VERSION ""

NS_ :

BS_:

BU_: VT TC Sprayer TECU

BO_ 2566835198 DM2: 22 Vector__XXX
 SG_ DTC5 : 144|32@1+ (1,0) [0|4294967295] "" Vector__XXX
 SG_ DTC4 : 112|32@1+ (1,0) [0|4294967295] "" Vector__XXX
 SG_ DTC3 : 80|32@1+ (1,0) [0|4294967295] "" Vector__XXX
 SG_ DTC2 : 48|32@1+ (1,0) [0|4294967295] "" Vector__XXX
 SG_ DTC1 : 16|32@1+ (1,0) [0|4294967295] "" Vector__XXX

BO_ 2566734590 ICC: 8 Vector__XXX
 SG_ CertLaboratoryType_FirstDef m0 : 9|3@1+ (1,0) [0|7] "" Vector__XXX
 SG_ TestProtocolRevision_MSBits m1 : 11|2@1+ (1,0) [0|0] "" Vector__XXX
 SG_ MessageRevision M : 47|1@1+ (1,0) [0|0] "" Vector__XXX
 SG_ CertificationReferenceNumber : 48|16@1+ (1,0) [0|65535] "" Vector__XXX
 SG_ CertTypeTaskController m0 : 39|1@1+ (1,0) [0|1] "" Vector__XXX
 SG_ CertTypeTCWorkingSetMaster m0 : 38|1@1+ (1,0) [0|1] "" Vector__XXX
 SG_ CertTypeTCWorkingSetMember m0 : 37|1@1+ (1,0) [0|1] "" Vector__XXX
 SG_ CertTypeFileServer m0 : 36|1@1+ (1,0) [0|1] "" Vector__XXX
 SG_ CertTypeGPSReceiver m0 : 35|1@1+ (1,0) [0|1] "" Vector__XXX
 SG_ CertTypeMinimumECU m0 : 31|1@1+ (1,0) [0|1] "" Vector__XXX
 SG_ CertTypeTECUClass1 m0 : 30|1@1+ (1,0) [0|1] "" Vector__XXX
 SG_ CertTypeTECUClass2 m0 : 29|1@1+ (1,0) [0|1] "" Vector__XXX
 SG_ CertTypeTECUClass3 m0 : 28|1@1+ (1,0) [0|1] "" Vector__XXX
 SG_ CertTypeClass3ECU m0 : 27|1@1+ (1,0) [0|1] "" Vector__XXX
 SG_ CertTypeVirtualTerminal m0 : 26|1@1+ (1,0) [0|1] "" Vector__XXX
 SG_ CertTypeVTWorkingSetMaster m0 : 25|1@1+ (1,0) [0|1] "" Vector__XXX
 SG_ CertTypeVTWorkingSetMember m0 : 24|1@1+ (1,0) [0|1] "" Vector__XXX
 SG_ CertificationLaboratoryID : 13|11@1+ (1,0) [0|2047] "" Vector__XXX
 SG_ CertLaboratoryType_SecondDef m1 : 9|2@1+ (1,0) [0|3] "" Vector__XXX
 SG_ TestProtocolRevision : 6|3@1+ (1,0) [0|7] "" Vector__XXX
 SG_ TestProtocolPublicationYear : 0|6@1+ (1,2000) [2000|2061] "year" Vector__XXX

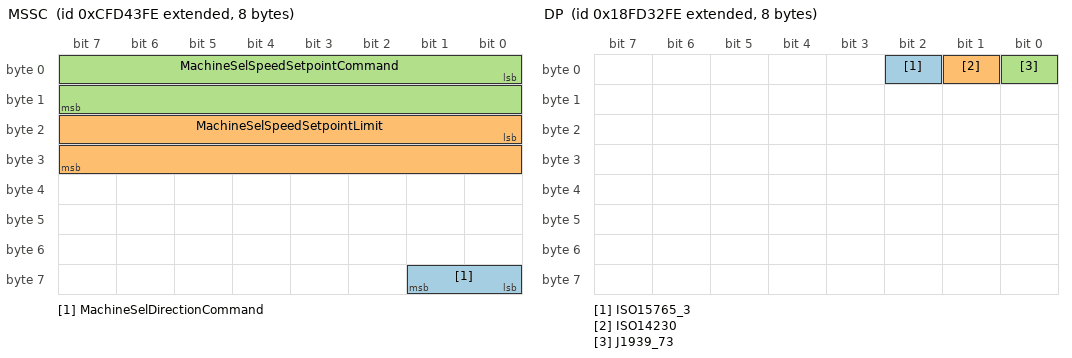
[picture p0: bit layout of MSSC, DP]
BO_ 2365408254 MSSC: 8 Vector__XXX
 SG_ MachineSelDirectionCommand : 56|2@1+ (1,0) [0|3] "" Vector__XXX
 SG_ MachineSelSpeedSetpointLimit : 16|16@1+ (0.001,0) [0|64255] "m/s" Vector__XXX
 SG_ MachineSelSpeedSetpointCommand : 0|16@1+ (0.001,0) [0|64255] "m/s" Vector__XXX

BO_ 2566730494 DP: 8 Vector__XXX
 SG_ ISO15765_3 : 2|1@1+ (1,0) [0|1] "" Vector__XXX
 SG_ ISO14230 : 1|1@1+ (1,0) [0|1] "" Vector__XXX
 SG_ J1939_73 : 0|1@1+ (1,0) [0|1] "" Vector__XXX

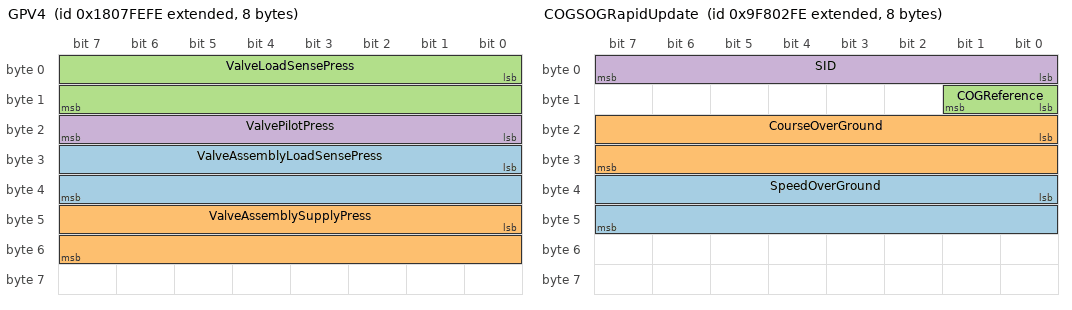
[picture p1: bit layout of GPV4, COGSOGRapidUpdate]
BO_ 2550660862 GPV4: 8 Vector__XXX
 SG_ ValveAssemblyLoadSensePress : 24|16@1+ (5,0) [0|321275] "kPa" Vector__XXX
 SG_ ValveAssemblySupplyPress : 40|16@1+ (5,0) [0|321275] "kPa" Vector__XXX
 SG_ ValveLoadSensePress : 0|16@1+ (5,0) [0|321275] "kPa" Vector__XXX
 SG_ ValvePilotPress : 16|8@1+ (16,0) [0|4000] "kPa" Vector__XXX

BO_ 2364547838 MSS: 9 Vector__XXX
 SG_ MachineSelectedSpeedLimitStatus : 61|3@1+ (1,0) [0|7] "" Vector__XXX
 SG_ MachineSelectedSpeedSource : 58|3@1+ (1,0) [0|7] "" Vector__XXX
 SG_ MachineSelectedDirection : 56|2@1+ (1,0) [0|3] "" Vector__XXX
 SG_ MachineSelectedDistance : 16|32@1+ (0.001,0) [0|4211081.215] "m" Vector__XXX
 SG_ MachineSelectedSpeed : 0|16@1+ (0.001,0) [0|65.535] "m/s" Vector__XXX

BO_ 2566835454 DM3: 0 Vector__XXX

BO_ 2365391616 IOS: 8 Vector__XXX
 SG_ ImplementOperatingStateCmd : 56|2@1+ (1,0) [0|3] "" Vector__XXX

BO_ 2365391360 AISO: 8 Vector__XXX
 SG_ StopAllImplOpTransitionNum : 48|8@1+ (1,0) [0|0] "" Vector__XXX
 SG_ StopAllImplementOperations : 56|2@1- (1,0) [0|3] "" Vector__XXX

BO_ 2314732286 COGSOGRapidUpdate: 8 Vector__XXX
 SG_ SpeedOverGround : 32|16@1+ (0.01,0) [0|655.32] "m/s" Vector__XXX
 SG_ CourseOverGround : 16|16@1+ (0.0001,0) [0|6.28318] "rad" Vector__XXX
 SG_ COGReference : 8|2@1+ (1,0) [0|3] "" Vector__XXX
 SG_ SID : 0|8@1+ (1,0) [0|252] "" Vector__XXX

BO_ 2358181630 SCMCC: 8 Vector__XXX
 SG_ MaxDesignatorStringLength m144 : 32|16@1+ (1,0) [0|65535] "" Vector__XXX
 SG_ BusyFlagParsing m149 : 33|1@1+ (1,0) [0|1] "" Vector__XXX
 SG_ ReceivedTAN m50 : 32|8@1+ (1,0) [0|255] "" Vector__XXX
 SG_ RecordedFunctionValue m51 : 32|32@1+ (1,0) [0|4294967295] "" Vector__XXX
 SG_ BusyFlagMemoryAccess m149 : 32|1@1+ (1,0) [0|1] "" Vector__XXX
 SG_ ExecutionIndicationResponseError m50 : 24|8@1+ (1,0) [0|255] "" Vector__XXX
 SG_ TAN m51 : 24|8@1+ (1,0) [0|255] "" Vector__XXX
 SG_ SequenceState m149 : 24|8@1+ (1,0) [0|255] "" Vector__XXX
 SG_ ReasonIndicator m48 : 24|8@1+ (1,0) [0|255] "" Vector__XXX
 SG_ GraphicsHeight m144 : 24|8@1+ (1,0) [32|255] "" Vector__XXX
 SG_ FunctionExecutionState m50 : 22|2@1+ (1,0) [0|3] "" Vector__XXX
 SG_ FunctionExecutionStateAck m52 : 22|2@1+ (1,0) [0|3] "" Vector__XXX
 SG_ StateID m50 : 16|6@1+ (1,0) [0|63] "" Vector__XXX
 SG_ ActualConfigurationLabel m0 : 16|8@1+ (1,0) [0|255] "" Vector__XXX
 SG_ ActualVersionLabel m0 : 16|8@1+ (1,0) [0|255] "" Vector__XXX
 SG_ GraphicsWidth m144 : 16|8@1+ (1,0) [32|255] "" Vector__XXX
 SG_ RecordedStateID m51 : 16|6@1+ (1,0) [0|63] "" Vector__XXX
 SG_ SequenceNumber m149 : 16|8@1+ (1,0) [0|255] "" Vector__XXX
 SG_ ObjectIdOfFirstFaultyObject m4 : 16|16@1+ (1,0) [0|65535] "" Vector__XXX
 SG_ RecordedFunctionID m51 : 8|8@1+ (1,0) [0|255] "" Vector__XXX
 SG_ MemoryStatus m145 : 8|8@1+ (1,0) [0|1] "" Vector__XXX
 SG_ VersionResponseError m1M : 8|8@1+ (1,0) [0|255] "" Vector__XXX
 SG_ ConfigLabelResponseError m2M : 8|8@1+ (1,0) [0|255] "" Vector__XXX
 SG_ TransferResponseError m3 : 8|8@1+ (1,0) [0|255] "" Vector__XXX
 SG_ ActivationResponseError m4 : 8|8@1+ (1,0) [0|255] "" Vector__XXX
 SG_ SCMState m149 : 8|8@1+ (1,0) [0|2] "" Vector__XXX
 SG_ FunctionID m50 : 8|8@1+ (1,0) [0|255] "" Vector__XXX
 SG_ SCVersion m144 : 8|8@1+ (1,0) [0|255] "" Vector__XXX
 SG_ CommandedSCCState m48 : 8|8@1+ (1,0) [0|1] "" Vector__XXX
 SG_ DeleteCommandResponseError m5 : 8|8@1+ (1,0) [0|255] "" Vector__XXX
 SG_ StoreCommandError m6 : 8|8@1+ (1,0) [0|255] "" Vector__XXX
 SG_ LoadResponseError m7 : 8|8@1+ (1,0) [0|255] "" Vector__XXX
 SG_ MessageCode M : 0|8@1+ (1,0) [0|255] "" Vector__XXX

BO_ 2358116094 SCCCM: 8 Vector__XXX
 SG_ OperatorConfirmationRequired3 m3 : 63|1@1+ (1,0) [0|1] "" Vector__XXX
 SG_ ClientFunctionErrorStatuts3 m3 : 56|4@1+ (1,0) [0|15] "" Vector__XXX
 SG_ IDOfFaultyClientFunction3 m3 : 48|8@1+ (1,0) [0|255] "" Vector__XXX
 SG_ OperatorConfirmationRequired2 m2 : 47|1@1+ (1,0) [0|1] "" Vector__XXX
 SG_ ClientFunctionErrorStatuts2 m2 : 40|4@1+ (1,0) [0|15] "" Vector__XXX
 SG_ ReceivedTAN m52 : 32|8@1+ (1,0) [0|255] "" Vector__XXX
 SG_ FunctionValue m0 : 32|32@1+ (1,0) [0|4294967295] "" Vector__XXX
 SG_ IDOfFaultyClientFunction2 m2 : 32|8@1+ (1,0) [0|255] "" Vector__XXX
 SG_ ClientFunctonErrorState m150 : 32|8@1+ (1,0) [0|255] "" Vector__XXX
 SG_ OperatorConfirmationRequired1 m1 : 31|1@1+ (1,0) [0|1] "" Vector__XXX
 SG_ TAN m50 : 24|8@1+ (1,0) [0|255] "" Vector__XXX
 SG_ ClientExecutionError m52 : 24|8@1+ (1,0) [0|255] "" Vector__XXX
 SG_ ClientFunctionErrorStatuts1 m1 : 24|4@1+ (1,0) [0|15] "" Vector__XXX
 SG_ ClientAbortError m49 : 24|8@1+ (1,0) [0|255] "" Vector__XXX
 SG_ SequenceState m150 : 24|8@1+ (1,0) [0|255] "" Vector__XXX
 SG_ FunctionExecutionState m50M : 22|2@1+ (1,0) [0|3] "" Vector__XXX
 SG_ NewFunctionExecutionState m52 : 22|2@1+ (1,0) [0|3] "" Vector__XXX
 SG_ NewStateID m52 : 16|6@1+ (1,0) [0|63] "" Vector__XXX
 SG_ IDOfFaultyClientFunction1 m1 : 16|8@1+ (1,0) [0|255] "" Vector__XXX
 SG_ StateID m50 : 16|6@1+ (1,0) [0|63] "" Vector__XXX
 SG_ SequenceNumber m150 : 16|8@1+ (1,0) [0|255] "" Vector__XXX
 SG_ NumberOfFaultyFunctions m53M : 8|8@1+ (1,0) [0|255] "" Vector__XXX
 SG_ RecordedFunctionID m52 : 8|8@1+ (1,0) [0|255] "" Vector__XXX
 SG_ SCCState m150 : 8|8@1+ (1,0) [0|2] "" Vector__XXX
 SG_ FunctionID m50 : 8|8@1+ (1,0) [0|255] "" Vector__XXX
 SG_ MemoryRequired m145 : 8|32@1+ (1,0) [0|4294967295] "bytes" Vector__XXX
 SG_ AddressSCCWSM m4 : 8|8@1+ (1,0) [0|253] "" Vector__XXX
 SG_ DeleteCommandType m5 : 8|8@1+ (1,0) [0|1] "" Vector__XXX
 SG_ MessageCode M : 0|8@1+ (1,0) [0|255] "" Vector__XXX

BO_ 2559835902 NM: 8 Vector__XXX
 SG_ ManufacturerCodeQualifierFlag m0 : 8|1@1+ (1,0) [0|1] "" Vector__XXX
 SG_ ECUInstanceQualifierFlag m0 : 9|1@1+ (1,0) [0|1] "" Vector__XXX
 SG_ FunctionInstanceQualifierFlag m0 : 10|1@1+ (1,0) [0|1] "" Vector__XXX
 SG_ FunctionQualifierFlag m0 : 11|1@1+ (1,0) [0|1] "" Vector__XXX
 SG_ VehicleSystemQualifierFlag m0 : 12|1@1+ (1,0) [0|1] "" Vector__XXX
 SG_ VehicleSystemInstanceQualifierFl m0 : 13|1@1+ (1,0) [0|1] "" Vector__XXX
 SG_ IndustryGroupQualifierFlag m0 : 14|1@1+ (1,0) [0|1] "" Vector__XXX
 SG_ ArbitraryAddressCapableQualifier m0 : 15|1@1+ (1,0) [0|1] "" Vector__XXX
 SG_ NMControlModeIndicator M : 16|4@1+ (1,0) [0|15] "" Vector__XXX
 SG_ CommandManufacturerCode m0 : 21|11@1+ (1,0) [0|2047] "" Vector__XXX
 SG_ CommandECUInstance m0 : 32|3@1+ (1,0) [0|7] "" Vector__XXX
 SG_ CommandFunctionInstance m0 : 35|5@1+ (1,0) [0|31] "" Vector__XXX
 SG_ CommandFunction m0 : 40|8@1+ (1,0) [0|255] "" Vector__XXX
 SG_ CommandVehicleSystem m0 : 49|7@1+ (1,0) [0|127] "" Vector__XXX
 SG_ CommandIndustryGroup m0 : 60|3@1+ (1,0) [0|7] "" Vector__XXX
 SG_ CommandVehicleSystemInstance m0 : 56|4@1+ (1,0) [0|15] "" Vector__XXX
 SG_ CommandArbitraryAddressCapable m0 : 63|1@1+ (1,0) [0|1] "" Vector__XXX
 SG_ ErrorCode m4 : 0|8@1+ (1,0) [0|0] "" Vector__XXX
 SG_ NameChecksum m0 : 0|8@1+ (1,0) [0|0] "" Vector__XXX

BO_ 2566843646 VI: 8 Vector__XXX
 SG_ VehicleIdentificationNumber : 0|8@1+ (1,0) [0|255] "per byte" Vector__XXX

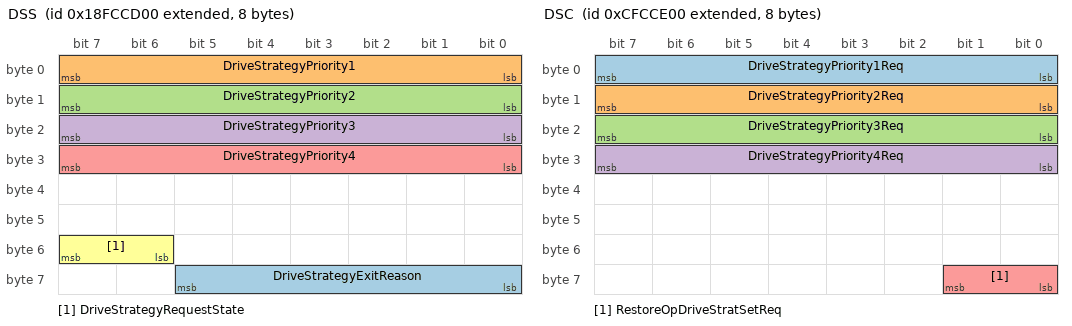
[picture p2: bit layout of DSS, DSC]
BO_ 2566704384 DSS: 8 Vector__XXX
 SG_ DriveStrategyExitReason : 56|6@1+ (1,0) [0|63] "" Vector__XXX
 SG_ DriveStrategyPriority1 : 0|8@1+ (1,0) [0|255] "" Vector__XXX
 SG_ DriveStrategyPriority2 : 8|8@1+ (1,0) [0|255] "" Vector__XXX
 SG_ DriveStrategyPriority3 : 16|8@1+ (1,0) [0|255] "" Vector__XXX
 SG_ DriveStrategyPriority4 : 24|8@1+ (1,0) [0|255] "" Vector__XXX
 SG_ DriveStrategyRequestState : 54|2@1+ (1,0) [0|3] "" Vector__XXX

BO_ 2365378048 DSC: 8 Vector__XXX
 SG_ DriveStrategyPriority1Req : 0|8@1+ (1,0) [0|255] "" Vector__XXX
 SG_ DriveStrategyPriority2Req : 8|8@1+ (1,0) [0|255] "" Vector__XXX
 SG_ DriveStrategyPriority3Req : 16|8@1+ (1,0) [0|255] "" Vector__XXX
 SG_ DriveStrategyPriority4Req : 24|8@1+ (1,0) [0|255] "" Vector__XXX
 SG_ RestoreOpDriveStratSetReq : 56|2@1+ (1,0) [0|3] "" Vector__XXX

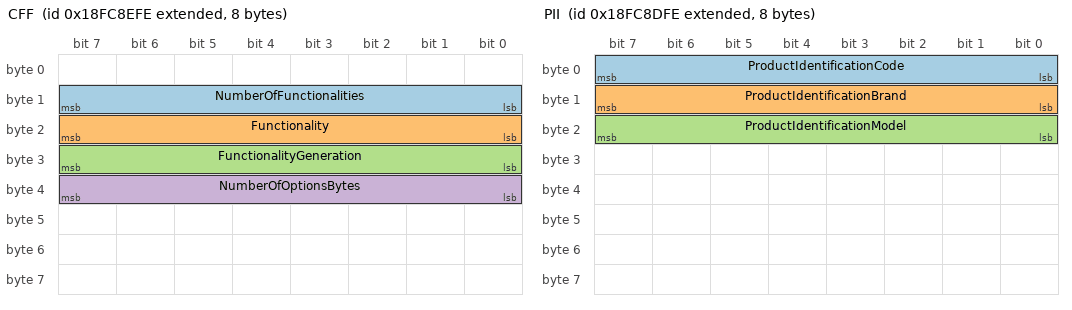
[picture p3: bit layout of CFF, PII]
BO_ 2566688510 CFF: 8 Vector__XXX
 SG_ NumberOfFunctionalities : 8|8@1- (1,0) [1|255] "" Vector__XXX
 SG_ Functionality : 16|8@1- (1,0) [0|255] "" Vector__XXX
 SG_ FunctionalityGeneration : 24|8@1- (1,0) [1|255] "" Vector__XXX
 SG_ NumberOfOptionsBytes : 32|8@1- (1,0) [0|255] "" Vector__XXX

BO_ 2566688254 PII: 8 Vector__XXX
 SG_ ProductIdentificationCode : 0|8@1- (1,0) [0|0] "" Vector__XXX
 SG_ ProductIdentificationBrand : 8|8@1- (1,0) [0|0] "" Vector__XXX
 SG_ ProductIdentificationModel : 16|8@1- (1,0) [0|0] "" Vector__XXX

CM_ BO_ 2566835198 "Previously active diagnostic trouble codes";
CM_ SG_ 2566835198 DTC5 "Diagnostic Trouble Code";
CM_ SG_ 2566835198 DTC4 "Diagnostic Trouble Code";
CM_ SG_ 2566835198 DTC3 "Diagnostic Trouble Code";
CM_ SG_ 2566835198 DTC2 "Diagnostic Trouble Code";
CM_ SG_ 2566835198 DTC1 "Diagnostic Trouble Code";
CM_ BO_ 2566734590 "ISOBUS compliance certification";
CM_ SG_ 2566734590 CertLaboratoryType_FirstDef "Approving body for the certification laboratory.";
CM_ SG_ 2566734590 MessageRevision "This parameter distinguishes the format of the ISOBUS Compliance Certification message in the second 
edition from the format in the third and later editions.";
CM_ SG_ 2566734590 CertificationReferenceNumber "ISOBUS Compliance certification reference number";
CM_ SG_ 2566734590 CertTypeTaskController "ISOBUS Compliance certification type - Task Controller";
CM_ SG_ 2566734590 CertTypeTCWorkingSetMaster "ISOBUS Compliance certification type - TC working set master";
CM_ SG_ 2566734590 CertTypeTCWorkingSetMember "ISOBUS Compliance certification type - TC working set member";
CM_ SG_ 2566734590 CertTypeFileServer "ISOBUS Compliance certification type - File server";
CM_ SG_ 2566734590 CertTypeGPSReceiver "ISOBUS Compliance certification type - GPS receiver";
CM_ SG_ 2566734590 CertTypeMinimumECU "ISOBUS Compliance certification type - Minimum ECU";
CM_ SG_ 2566734590 CertTypeTECUClass1 "ISOBUS Compliance certification type - TECU Class 1";
CM_ SG_ 2566734590 CertTypeTECUClass2 "ISOBUS Compliance certification type - TECU Class 2";
CM_ SG_ 2566734590 CertTypeTECUClass3 "ISOBUS Compliance certification type - TECU Class 3";
CM_ SG_ 2566734590 CertTypeClass3ECU "ISOBUS Compliance certification type - Class 3 ECU";
CM_ SG_ 2566734590 CertTypeVirtualTerminal "ISOBUS Compliance certification type - Virtual terminal";
CM_ SG_ 2566734590 CertTypeVTWorkingSetMaster "ISOBUS Compliance certification type - VT working set master";
CM_ SG_ 2566734590 CertTypeVTWorkingSetMember "ISOBUS Compliance certification type - VT working set member";
CM_ SG_ 2566734590 CertificationLaboratoryID "ISOBUS Compliance certification laboratory ID";
CM_ SG_ 2566734590 CertLaboratoryType_SecondDef "Approving body for the certification laboratory.";
CM_ SG_ 2566734590 TestProtocolRevision "ISOBUS compliance certificate revision";
CM_ SG_ 2566734590 TestProtocolPublicationYear "ISOBUS compliance certification year";
CM_ BO_ 2365408254 "Machine Selected Speed Command";
CM_ SG_ 2365408254 MachineSelDirectionCommand "Machine selected direction command";
CM_ SG_ 2365408254 MachineSelSpeedSetpointLimit "Machine selected speed setpoint limit";
CM_ SG_ 2365408254 MachineSelSpeedSetpointCommand "Machine selected speed setpoint command";
CM_ BO_ 2566730494 "ECU diagnostic protocol";
CM_ SG_ 2566730494 ISO15765_3 "ISO 15765-3 (UDS on CAN)";
CM_ SG_ 2566730494 ISO14230 "ISO 14230 (KWP 2000 over K line)";
CM_ SG_ 2566730494 J1939_73 "J1939-73";
CM_ BO_ 2550660862 "General purpose valve load sense pressure";
CM_ SG_ 2550660862 ValveAssemblyLoadSensePress "The maximum pressure of a valve assembly's current collective load sense pressures where a valve assembly can ...";
CM_ SG_ 2550660862 ValveAssemblySupplyPress "Pressure of the hydraulic supply port to a valve assembly.";
CM_ SG_ 2550660862 ValveLoadSensePress "The maximum of the currently measured pressures of a valve's work port A and work port B.";
CM_ SG_ 2550660862 ValvePilotPress "Pressure of a valve's pilot supply port.";
CM_ BO_ 2364547838 "Machine selected speed";
CM_ SG_ 2364547838 MachineSelectedSpeedLimitStatus "Machine selected speed limit status";
CM_ SG_ 2364547838 MachineSelectedSpeedSource "Machine selected speed source";
CM_ SG_ 2364547838 MachineSelectedDirection "Machine selected direction";
CM_ SG_ 2364547838 MachineSelectedDistance "Machine selected Distance";
CM_ SG_ 2364547838 MachineSelectedSpeed "Machine selected Speed";
CM_ BO_ 2566835454 "Diagnostic data clear/reset of previously active DTCs.";
CM_ BO_ 2365391616 "Implement operating state command";
CM_ BO_ 2365391360 " All implements stop operations switch state";
CM_ SG_ 2365391360 StopAllImplOpTransitionNum "This parameter indicates the number of transitions from Permit (01) to Stop (00) since power up of 
the Stop all implement operations parameter. The parameter resets to zero on the next transition after 
reporting the maximum value.";
CM_ BO_ 2314732286 "This PGN is a single frame PGN that provides Course Over Ground(COG)and Speed Over Ground(SOG).

Being a single frame Msg,as opposed to other PGNs that include COG and SOG and are defined as multi-packet,this PGN lends itself to being transmitted more f";
CM_ SG_ 2314732286 CourseOverGround "The direction of the path over ground actually followed by a vessel.";
CM_ SG_ 2314732286 COGReference "0 = True, 
1 = Magnetic, 
2 = Error, 
3 = Null";
CM_ SG_ 2314732286 SID "An upward counting number used to tie related information together between different PGNs.For example,SID would be used to tie together COG,SOG and RAIM values to a given Pos.255=no valid Pos fix to tie it to.Range 0 to 250 for valid Pos fixes.";
CM_ BO_ 2358181630 "Sequence Control Master to Sequence Control Client";
CM_ SG_ 2358181630 MaxDesignatorStringLength "Maximum number of displayed characters for designator strings";
CM_ SG_ 2358181630 GraphicsHeight "Number of pixels on the Y axis for graphics objects";
CM_ SG_ 2358181630 GraphicsWidth "Number of pixels on the X axis for graphics objects";
CM_ SG_ 2358181630 ObjectIdOfFirstFaultyObject "Object ID of first faulty object";
CM_ SG_ 2358181630 MemoryStatus "Status of the SCMasterMemoryResponse";
CM_ SG_ 2358181630 VersionResponseError "Error code of the SCDVersionResponse";
CM_ SG_ 2358181630 ConfigLabelResponseError "Error code of SCDConfigurationLabelResponse";
CM_ SG_ 2358181630 TransferResponseError "Error code of the SCDTransferResponse";
CM_ SG_ 2358181630 SCMState "State of sending SCM";
CM_ SG_ 2358181630 SCVersion "Version of supported SC standard";
CM_ SG_ 2358181630 MessageCode "Message code of the SCMCC message";
CM_ BO_ 2358116094 "Sequence Control Client to Sequence Control Master";
CM_ SG_ 2358116094 ClientAbortError "Error code of a SCClientAbort";
CM_ SG_ 2358116094 MemoryRequired "Volatile memory required, number of bytes of the SCD to upload";
CM_ SG_ 2358116094 AddressSCCWSM "Source address of SCC's working set master";
CM_ BO_ 2566843646 "Byte: 1-n Vehicle Identification Number 
Delimiter (ASCII “*”)";
CM_ SG_ 2566843646 VehicleIdentificationNumber "Vehicle Identification Number (VIN) as assigned by the vehicle manufacturer.";
CM_ BO_ 2566704384 "Message sent from the tractor to the implement to indicate the current status, of the drive strategy priority 
structure, which indicates the priority of the multiple powertrain functions. ";
CM_ SG_ 2566704384 DriveStrategyExitReason "Parameter used to indicate why the drive strategy subsystem cannot currently accept remote commands or 
has most recently stopped accepting remote commands.";
CM_ SG_ 2566704384 DriveStrategyPriority1 "This parameter indicates the current Tractor drive strategy priority structure, which determines the balance 
between  fuel  economy/consumption  and  the  torque  reserve  of  the  engine.  This  parameter  indicates  the 
highest priority. ";
CM_ SG_ 2566704384 DriveStrategyPriority2 "This parameter indicates the current Tractor drive strategy priority structure, which determines the balance 
between  fuel  economy/consumption  and  the  torque  reserve  of  the  engine.  This  parameter  indicates 
 the second to highest priority. ";
CM_ SG_ 2566704384 DriveStrategyPriority3 "This parameter indicates the current Tractor drive strategy priority structure, which determines the balance 
between  fuel  economy/consumption  and  the  torque  reserve  of  the  engine.  This  parameter  indicates 
 the third to highest priority. ";
CM_ SG_ 2566704384 DriveStrategyPriority4 "This parameter indicates the current Tractor drive strategy priority structure, which determines the balance 
between  fuel  economy/consumption  and  the  torque  reserve  of  the  engine.  This  parameter  indicates  the 
lowest priority. ";
CM_ SG_ 2566704384 DriveStrategyRequestState "This  parmeter  reports  the  tractor's  state  associated  with  Drive  Strategy  requests  that  are 
transient/temporary/one-shot.";
CM_ SG_ 2365378048 DriveStrategyPriority1Req "This parameter used to request an alteration to the tractor drive strategy priority structure, which determines 
the  balance  between  fuel  economy/consumption  and  the  torque  reserve  of  the  engine - the highest priority request.";
CM_ SG_ 2365378048 DriveStrategyPriority2Req "This parameter used to request an alteration to the tractor drive strategy priority structure, which determines 
the  balance  between  fuel  economy/consumption  and  the  torque  reserve  of  the  engine - the second to highest priority request.";
CM_ SG_ 2365378048 DriveStrategyPriority3Req "This parameter used to request an alteration to the tractor drive strategy priority structure, which determines 
the  balance  between  fuel  economy/consumption  and  the  torque  reserve  of  the  engine - the third to highest priority request.";
CM_ SG_ 2365378048 DriveStrategyPriority4Req "This parameter used to request an alteration to the tractor drive strategy priority structure, which determines 
the  balance  between  fuel  economy/consumption  and  the  torque  reserve  of  the  engine - the lowest priority request.  ";
CM_ SG_ 2365378048 RestoreOpDriveStratSetReq "This parameter requests the drive strategy subsystem to restore the settings for drive strategy to the state 
before automation was ended. ";
CM_ BO_ 2566688510 "This message identifies all the functionalities, functionality generation and functionality options, supported by 
control functions.";
CM_ SG_ 2566688510 Functionality "This parameter reports which functionalities are supported by a control function connected to the ISO 11783 
network. ";
CM_ SG_ 2566688510 FunctionalityGeneration "This parameter reports the generation of the functionality provided by a control function connected to the ISO 11783 network.";
CM_ SG_ 2566688510 NumberOfOptionsBytes "This parameter reports the number of bytes that follow to report which options are supported by a functionality 
provided  by  a  control  function  connected  to  the  ISO  11783  network.";
CM_ BO_ 2566688254 "Product Identification Information: Each control function of a product shall respond with the same product identification information when it 
receives the Request PGN message for this PGN.";
CM_ SG_ 2566688254 ProductIdentificationCode "The Product Identification Code as assigned by the manufacturer correspondents with the number on the type 
plate of a product.";
CM_ SG_ 2566688254 ProductIdentificationBrand "Specifies  the  brand  of  a  product.  
The  combination  of  the  Product Identification Code and the Product Identification Brand shall make the product unique in the world.";
CM_ SG_ 2566688254 ProductIdentificationModel "The Product Identification Model specifies a unique product within a Brand. ";
BA_DEF_ SG_  "DDI" INT 0 65535;
BA_DEF_ BO_  "SingleFrame" INT 0 1;
BA_DEF_ BO_  "VFrameFormat" ENUM  "StandardCAN","ExtendedCAN","reserved","J1939PG","vector_leerstring";
BA_DEF_ BO_  "GenMsgSendType" ENUM  "cyclic","NotUsed","IfActive","NotUsed","NotUsed","NotUsed","NotUsed","NotUsed","noMsgSendType","vector_leerstring";
BA_DEF_ BO_  "GenMsgCycleTime" INT 0 3600000;
BA_DEF_ BO_  "GenMsgRequestable" INT 0 1;
BA_DEF_ BO_  "GenMsgCycleTimeFast" INT 0 3600000;
BA_DEF_ SG_  "SPN" INT 0 524287;
BA_DEF_ SG_  "GenSigSendType" ENUM  "Cyclic","OnWrite","OnWriteWithRepetition","OnChange","OnChangeWithRepetition","IfActive","IfActiveWithRepetition","NoSigSendType";
BA_DEF_ SG_  "SigType" ENUM  "Default","Range","RangeSigned","ASCII","Discrete","Control","ReferencePGN","DTC","StringDelimiter","StringLength","StringLengthControl","MessageCounter","MessageChecksum";
BA_DEF_ SG_  "GenSigStartValue" INT -2147483648 2147483647;
BA_DEF_ SG_  "SystemSignalLongSymbol" STRING ;
BA_DEF_DEF_  "DDI" 0;
BA_DEF_DEF_  "SingleFrame" 1;
BA_DEF_DEF_  "VFrameFormat" "J1939PG";
BA_DEF_DEF_  "GenMsgSendType" "noMsgSendType";
BA_DEF_DEF_  "GenMsgCycleTime" 0;
BA_DEF_DEF_  "GenMsgRequestable" 1;
BA_DEF_DEF_  "GenMsgCycleTimeFast" 0;
BA_DEF_DEF_  "SPN" 0;
BA_DEF_DEF_  "GenSigSendType" "NoSigSendType";
BA_DEF_DEF_  "SigType" "Default";
BA_DEF_DEF_  "GenSigStartValue" 0;
BA_DEF_DEF_  "SystemSignalLongSymbol" "";
BA_ "GenMsgCycleTime" BO_ 2365408254 100;
BA_ "GenMsgSendType" BO_ 2365408254 0;
BA_ "GenMsgCycleTime" BO_ 2550660862 100;
BA_ "GenMsgSendType" BO_ 2550660862 0;
BA_ "GenMsgCycleTime" BO_ 2314732286 250;
BA_ "GenMsgCycleTime" BO_ 2566704384 500;
BA_ "GenMsgSendType" BO_ 2566704384 0;
BA_ "GenMsgCycleTimeFast" BO_ 2365378048 100;
BA_ "GenMsgCycleTime" BO_ 2365378048 500;
BA_ "GenMsgSendType" BO_ 2365378048 0;
BA_ "SigType" SG_ 2566835198 DTC5 7;
BA_ "SigType" SG_ 2566835198 DTC4 7;
BA_ "SigType" SG_ 2566835198 DTC3 7;
BA_ "SigType" SG_ 2566835198 DTC2 7;
BA_ "SigType" SG_ 2566835198 DTC1 7;
BA_ "SPN" SG_ 2566734590 CertLaboratoryType_FirstDef 4315;
BA_ "SPN" SG_ 2566734590 MessageRevision 7446;
BA_ "SPN" SG_ 2566734590 CertificationReferenceNumber 4330;
BA_ "SPN" SG_ 2566734590 CertTypeTaskController 4325;
BA_ "SPN" SG_ 2566734590 CertTypeTCWorkingSetMaster 4326;
BA_ "SPN" SG_ 2566734590 CertTypeTCWorkingSetMember 4327;
BA_ "SPN" SG_ 2566734590 CertTypeFileServer 4328;
BA_ "SPN" SG_ 2566734590 CertTypeGPSReceiver 4329;
BA_ "SPN" SG_ 2566734590 CertTypeMinimumECU 4317;
BA_ "SPN" SG_ 2566734590 CertTypeTECUClass1 4318;
BA_ "SPN" SG_ 2566734590 CertTypeTECUClass2 4319;
BA_ "SPN" SG_ 2566734590 CertTypeTECUClass3 4320;
BA_ "SPN" SG_ 2566734590 CertTypeClass3ECU 4321;
BA_ "SPN" SG_ 2566734590 CertTypeVirtualTerminal 4322;
BA_ "SPN" SG_ 2566734590 CertTypeVTWorkingSetMaster 4323;
BA_ "SPN" SG_ 2566734590 CertTypeVTWorkingSetMember 4324;
BA_ "SPN" SG_ 2566734590 CertificationLaboratoryID 4316;
BA_ "SPN" SG_ 2566734590 CertLaboratoryType_SecondDef 4315;
BA_ "SPN" SG_ 2566734590 TestProtocolRevision 4314;
BA_ "SPN" SG_ 2566734590 TestProtocolPublicationYear 4313;
BA_ "SigType" SG_ 2365408254 MachineSelDirectionCommand 4;
BA_ "SPN" SG_ 2365408254 MachineSelDirectionCommand 4312;
BA_ "SigType" SG_ 2365408254 MachineSelSpeedSetpointLimit 1;
BA_ "SPN" SG_ 2365408254 MachineSelSpeedSetpointLimit 4311;
BA_ "SigType" SG_ 2365408254 MachineSelSpeedSetpointCommand 1;
BA_ "SPN" SG_ 2365408254 MachineSelSpeedSetpointCommand 4310;
BA_ "SigType" SG_ 2550660862 ValveAssemblyLoadSensePress 1;
BA_ "SPN" SG_ 2550660862 ValveAssemblyLoadSensePress 4088;
BA_ "SigType" SG_ 2550660862 ValveAssemblySupplyPress 1;
BA_ "SPN" SG_ 2550660862 ValveAssemblySupplyPress 4089;
BA_ "SigType" SG_ 2550660862 ValveLoadSensePress 1;
BA_ "SPN" SG_ 2550660862 ValveLoadSensePress 4086;
BA_ "SigType" SG_ 2550660862 ValvePilotPress 1;
BA_ "SPN" SG_ 2550660862 ValvePilotPress 4087;
BA_ "SPN" SG_ 2364547838 MachineSelectedSpeedLimitStatus 4307;
BA_ "SPN" SG_ 2364547838 MachineSelectedSpeedSource 4308;
BA_ "SigType" SG_ 2364547838 MachineSelectedDirection 4;
BA_ "SPN" SG_ 2364547838 MachineSelectedDirection 4309;
BA_ "SPN" SG_ 2364547838 MachineSelectedDistance 4306;
BA_ "SPN" SG_ 2364547838 MachineSelectedSpeed 4305;
BA_ "SPN" SG_ 2365391616 ImplementOperatingStateCmd 5139;
BA_ "SPN" SG_ 2365391360 StopAllImplOpTransitionNum 7443;
BA_ "SPN" SG_ 2365391360 StopAllImplementOperations 5140;
BA_ "SigType" SG_ 2314732286 SpeedOverGround 1;
BA_ "SigType" SG_ 2314732286 CourseOverGround 1;
BA_ "SigType" SG_ 2314732286 COGReference 4;
BA_ "SigType" SG_ 2314732286 SID 1;
BA_ "GenSigStartValue" SG_ 2358181630 GraphicsHeight 32;
BA_ "SigType" SG_ 2358181630 ActualConfigurationLabel 9;
BA_ "SigType" SG_ 2358181630 ActualVersionLabel 9;
BA_ "GenSigStartValue" SG_ 2358181630 GraphicsWidth 32;
BA_ "SystemSignalLongSymbol" SG_ 2559835902 VehicleSystemInstanceQualifierFl "VehicleSystemInstanceQualifierFlag";
BA_ "SystemSignalLongSymbol" SG_ 2559835902 ArbitraryAddressCapableQualifier "ArbitraryAddressCapableQualifierFlag";
BA_ "SigType" SG_ 2566843646 VehicleIdentificationNumber 8;
BA_ "SPN" SG_ 2566843646 VehicleIdentificationNumber 237;
BA_ "SPN" SG_ 2566704384 DriveStrategyExitReason 5732;
BA_ "SPN" SG_ 2566704384 DriveStrategyPriority1 5727;
BA_ "SPN" SG_ 2566704384 DriveStrategyPriority2 5728;
BA_ "SPN" SG_ 2566704384 DriveStrategyPriority3 5729;
BA_ "SPN" SG_ 2566704384 DriveStrategyPriority4 5730;
BA_ "SPN" SG_ 2566704384 DriveStrategyRequestState 5731;
BA_ "SPN" SG_ 2365378048 DriveStrategyPriority1Req 5733;
BA_ "SPN" SG_ 2365378048 DriveStrategyPriority2Req 5734;
BA_ "SPN" SG_ 2365378048 DriveStrategyPriority3Req 5735;
BA_ "SPN" SG_ 2365378048 DriveStrategyPriority4Req 5736;
BA_ "SPN" SG_ 2365378048 RestoreOpDriveStratSetReq 5737;
BA_ "GenSigStartValue" SG_ 2566688510 NumberOfFunctionalities 1;
BA_ "GenSigStartValue" SG_ 2566688510 FunctionalityGeneration 1;
BA_ "SPN" SG_ 2566688254 ProductIdentificationCode 6699;
BA_ "SigType" SG_ 2566688254 ProductIdentificationCode 8;
BA_ "SPN" SG_ 2566688254 ProductIdentificationBrand 6701;
BA_ "SigType" SG_ 2566688254 ProductIdentificationBrand 8;
BA_ "SPN" SG_ 2566688254 ProductIdentificationModel 6701;
BA_ "SigType" SG_ 2566688254 ProductIdentificationModel 8;
VAL_ 2566734590 CertLaboratoryType_FirstDef 7 "Not available (not certified) " 0 "Non-certified laboratory/self-test" 1 "AEF certified laboratory " 2 "Reserved " ;
VAL_ 2566734590 MessageRevision 1 "Third and later edition message revision" 0 "Format of message in second edition." ;
VAL_ 2566734590 CertificationReferenceNumber 0 "NotCertified" 1 "CertificationTestPerformed" ;
VAL_ 2566734590 CertTypeTaskController 0 "NotCertified" 1 "CertificationTestPerformed" ;
VAL_ 2566734590 CertTypeTCWorkingSetMaster 0 "NotCertified" 1 "CertificationTestPerformed" ;
VAL_ 2566734590 CertTypeTCWorkingSetMember 0 "NotCertified" 1 "CertificationTestPerformed" ;
VAL_ 2566734590 CertTypeFileServer 0 "NotCertified" 1 "CertificationTestPerformed" ;
VAL_ 2566734590 CertTypeGPSReceiver 0 "NotCertified" 1 "CertificationTestPerformed" ;
VAL_ 2566734590 CertTypeMinimumECU 0 "NotCertified" 1 "CertificationTestPerformed" ;
VAL_ 2566734590 CertTypeTECUClass1 0 "NotCertified" 1 "CertificationTestPerformed" ;
VAL_ 2566734590 CertTypeTECUClass2 0 "NotCertified" 1 "CertificationTestPerformed" ;
VAL_ 2566734590 CertTypeTECUClass3 0 "NotCertified" 1 "CertificationTestPerformed" ;
VAL_ 2566734590 CertTypeClass3ECU 0 "NotCertified" 1 "CertificationTestPerformed" ;
VAL_ 2566734590 CertTypeVirtualTerminal 0 "NotCertified" 1 "CertificationTestPerformed" ;
VAL_ 2566734590 CertTypeVTWorkingSetMaster 0 "NotCertified" 1 "CertificationTestPerformed" ;
VAL_ 2566734590 CertTypeVTWorkingSetMember 0 "NotCertified" 1 "CertificationTestPerformed" ;
VAL_ 2566734590 CertLaboratoryType_SecondDef 3 "Not available (not certified) " 0 "Non-certified Laboratory/self-certification" 1 "AEF certified laboratory " 2 "Reserved " ;
VAL_ 2566734590 TestProtocolRevision 0 "FirstRevision" 1 "SecondRevision" 2 "ThirdRevision" 3 "NotAvailable" ;
VAL_ 2365408254 MachineSelDirectionCommand 0 "Reverse" 1 "Forward" 2 "Reserved" 3 "DontCare" ;
VAL_ 2364547838 MachineSelectedSpeedLimitStatus 0 "NotLimited" 1 "OperatorLimited_Controlled" 2 "LimitedHigh" 3 "LimitedLow" 4 "Reserved" 5 "Reserved" 6 "NonRecoverableFault" 7 "NotAvailable" ;
VAL_ 2364547838 MachineSelectedSpeedSource 0 "WheelBasedSpeed" 1 "GroundBasedSpeed" 2 "NavigationBasedSpeed" 3 "BlendedSpeed" 4 "SimulatedSpeed" 5 "Reserved" 6 "Reserved" 7 "NotAvailable" ;
VAL_ 2364547838 MachineSelectedDirection 0 "Reverse" 1 "Forward" 2 "ErrorIndication" 3 "NotAvailable" ;
VAL_ 2365391616 ImplementOperatingStateCmd 0 "SetImplementToFieldWorkingState" 1 "SetImplementToTransportState" 2 "SetImplementToParkState" 3 "TakeNoAction" ;
VAL_ 2365391360 StopAllImplementOperations 0 "StopImplementOperations" 1 "PermitAllImplementsToON " 2 "ErrorIndication" 3 "NotAvailable " ;
VAL_ 2314732286 COGReference 0 "True" 1 "Magnetic" 2 "Error" 3 "Null" ;
VAL_ 2314732286 SID 255 "nVldPsFxTTItTRng0T250FrVldPstnFx" ;
VAL_ 2358181630 BusyFlagParsing 0 "NotBusy" 1 "SCMIsParsingAnSCD" ;
VAL_ 2358181630 BusyFlagMemoryAccess 0 "NotBusy" 1 "BusyWithNonVolatileMemoryAccess" ;
VAL_ 2358181630 ExecutionIndicationResponseError 0 "NoError" 1 "FunctionIDNotDefined" 2 "StateIDNotDefined" 3 "FunctionExecutionStateMismatch" 4 "SCMOutOfMemory" 5 "PlayBackContinues" 6 "PlayBackHaltedDueToOperator" 255 "GeneralError" ;
VAL_ 2358181630 SequenceState 1 "Ready" 2 "Recording" 3 "RecordingCompletition" 4 "PlayBack" 5 "Abort" 255 "SequenceStateNotAvailable" ;
VAL_ 2358181630 ReasonIndicator 1 "StatusChangeOnOperatorCommand" 2 "SCCNotPartOfSelectedSCS" 3 "SCCIsPartOfSelectedSCS" 255 "NoSpecificReason" ;
VAL_ 2358181630 FunctionExecutionState 0 "FunctionExecStartedAndCompleted" 1 "FunctionExecutionStarted" 2 "FunctionExecutionCompleted" 3 "ErrorDuringExecution" ;
VAL_ 2358181630 FunctionExecutionStateAck 0 "AckOfFuncExecStartAndCompletion" 1 "AckOfFunctionExecutionStarted" 2 "AckOfFunctionExecutionCompleted" 3 "AckErrorDuringExecution" ;
VAL_ 2358181630 SequenceNumber 255 "NoSequenceAvailable" ;
VAL_ 2358181630 MemoryStatus 0 "EnoughMemoryAvailable" 1 "NotEnoughMemoryAvailable" ;
VAL_ 2358181630 VersionResponseError 0 "NoError" 1 "NoMatchingSCDStored" 255 "GeneralError" ;
VAL_ 2358181630 ConfigLabelResponseError 0 "NoError" 1 "NoMatchingSCDStored" 255 "GeneralError" ;
VAL_ 2358181630 TransferResponseError 0 "NoError" 1 "ErrorOccurredDuringTransfer" 255 "GeneralError" ;
VAL_ 2358181630 ActivationResponseError 0 "NoError" 1 "UnknownObjectType" 2 "BasicObjectDoesNotExist" 3 "ReferencedFunctObjDoesNotExist" 4 "ReferencedStateObjDoesNotExist" 5 "ReferencedStringObjDoesNotExist" 6 "ReferencedGraphObjDoesNotExist" 7 "ObjectIDIsNotUnique" 8 "FunctionIDIsNotUnique" 9 "StateIDIsNotUnique" 10 "DesignatorStringthLengthIsZero" 11 "InvalidGraphicObject" 12 "SCDVersionLabelLengthIncorrect" 13 "SCDConfigLabelLengthIncorrect" 14 "SCVersionNotSupportedBySCM" 255 "GeneralError" ;
VAL_ 2358181630 SCMState 0 "Inactive" 1 "Active" 2 "Initialization" ;
VAL_ 2358181630 SCVersion 0 "DIS" 1 "FDIS" 2 "IS" ;
VAL_ 2358181630 CommandedSCCState 0 "Disabled" 1 "Enabled" ;
VAL_ 2358181630 DeleteCommandResponseError 0 "NoError" 1 "SCDDoesNotExist" 255 "GeneralError" ;
VAL_ 2358181630 StoreCommandError 0 "NoError" 1 "SCDWasNotCompletelyParsed" 2 "NotEnoughNonVolatileMemory" 255 "GeneralError" ;
VAL_ 2358181630 LoadResponseError 0 "NoError" 1 "SCDNotFound" 2 "FileSystemErrorOrDataCorruption" 3 "NotEnoughVolatileMemoryAvailable" 255 "GeneralError" ;
VAL_ 2358181630 MessageCode 1 "SCDVersionResponse" 2 "SCDConfigurationLabelResponse" 3 "SCDTransferResponse" 4 "SCDActivationResponse" 5 "SCDDeleteResponse" 6 "SCDStoreResponse" 7 "SCDLoadResponse" 48 "SCStateCommand" 50 "SCExecutionIndicationResponse" 51 "SCMasterExecutionCommand" 52 "SCClientExecutionAcknowledgement" 53 "SCClientFunctionErrorRequest" 144 "SCMasterCapablilityResponse" 145 "SCMasterMemoryResponse" 149 "SCMasterStatus" ;
VAL_ 2358116094 OperatorConfirmationRequired3 0 "no" 1 "yes" ;
VAL_ 2358116094 ClientFunctionErrorStatuts3 1 "OneTimeError" 2 "PermanentError" 3 "ClientFunctionIsLocked" 4 "ClientFunctionIsDeactivated" 15 "GeneralError" ;
VAL_ 2358116094 OperatorConfirmationRequired2 0 "no" 1 "yes" ;
VAL_ 2358116094 ClientFunctionErrorStatuts2 1 "OneTimeError" 2 "PermanentError" 3 "ClientFunctionIsLocked" 4 "ClientFunctionIsDeactivated" 15 "GeneralError" ;
VAL_ 2358116094 ClientFunctonErrorState 0 "NoError" 1 "ErrorStateNotChanged" 2 "ErrorStateChanged" 3 "ErrorStateReqConfirmationChanged" 255 "ErrorStateNotAvailable" ;
VAL_ 2358116094 OperatorConfirmationRequired1 0 "no" 1 "yes" ;
VAL_ 2358116094 ClientExecutionError 0 "NoError" 1 "ErrorInTheFunction" 2 "OperatorInteraction" 3 "ConditionsOfSCCAllowNoExecution" 255 "GeneralError" ;
VAL_ 2358116094 ClientFunctionErrorStatuts1 1 "OneTimeError" 2 "PermanentError" 3 "ClientFunctionIsLocked" 4 "ClientFunctionIsDeactivated" 15 "GeneralError" ;
VAL_ 2358116094 ClientAbortError 1 "TimeoutOnStatusMessage" 2 "OperatorInteraction" 3 "ErrorDuringFunctionExecution" 255 "GeneralError" ;
VAL_ 2358116094 SequenceState 1 "Ready" 2 "Recording" 4 "PlayBack" 5 "Abort" 255 "SequenceStateNotAvailable" ;
VAL_ 2358116094 FunctionExecutionState 0 "FunctionExecStartedAndCompleted" 1 "FunctionExecutionStarted" 2 "FunctionExecutionCompleted" 3 "ErrorDuringExecution" ;
VAL_ 2358116094 NewFunctionExecutionState 0 "FunctionExecStartedAndCompleted" 1 "FunctionExecutionStarted" 2 "FunctionExecutionCompleted" 3 "ErrorDuringExecution" ;
VAL_ 2358116094 SequenceNumber 255 "NoSequenceAvailable" ;
VAL_ 2358116094 SCCState 0 "Disabled" 1 "Enabled" 2 "Initialization" ;
VAL_ 2358116094 DeleteCommandType 0 "DeleteSCDInVolatileMemory" 1 "DeleteSCDInNonVolatileMemory" ;
VAL_ 2358116094 MessageCode 1 "SCDVersionRequest" 2 "SCDConfigurationLabelRequest" 3 "SCDTransfer" 4 "SCDActivationCommand" 5 "SCDDeleteCommand" 6 "SCDStoreCommand" 7 "SCDLoadCommand" 49 "SCClientAbort" 50 "SCExecutionIndication" 52 "SCClientExecutionStatus" 53 "SCClientFunctionErrorResponse" 144 "SCMasterCapabilityRequest" 145 "SCMasterMemoryRequest" 150 "SCClientStatus" ;
VAL_ 2559835902 NMControlModeIndicator 0 "SetPendingName" 1 "PendingName" 2 "CurrentName" 3 "NameACK" 4 "NameNACK" 5 "ReqPendingName" 6 "ReqCurrentName" 7 "AdoptPendingName" 8 "ReqNameAddressClaim" ;
VAL_ 2559835902 ErrorCode 0 "Security not satisfied" 1 "Item(s) not allowed to change" 2 "Item conflict" 3 "Checksum does not match" 4 "Pending Name not set" 255 "Not Available" 5 "Other" ;
VAL_ 2566704384 DriveStrategyExitReason 0 "No reason/all clear " 1 "Operator presence not detected " 2 "Implement released control of function " 3 "Operator override of function " 4 "Operator control not in valid position" 5 "Remote command timeout" 6 "Remote command out of range/invalid " 7 "Function not calibrated " 8 "Operator control fault" 9 "Function fault " 22 "Vehicle transmission gear does not allow remote commands" 62 "Error " 63 "Not available (parameter not supported) " ;
VAL_ 2566704384 DriveStrategyPriority1 0 "Enable maximum draft power control " 1 "Enable constant PTO speed control" 2 "Enable wheel speed/PTO speed ratio control" 3 "Enable minimum engine speed control" 4 "Enable engine economy control " 5 "Enable maximum hydraulic power control" 6 "Enable maximum electric power control" 253 "Requested mode not supported " 254 "Error or reserved" 255 "Not available/Don't care " ;
VAL_ 2566704384 DriveStrategyPriority2 0 "Enable maximum draft power control " 1 "Enable constant PTO speed control" 2 "Enable wheel speed/PTO speed ratio control" 3 "Enable minimum engine speed control" 4 "Enable engine economy control " 5 "Enable maximum hydraulic power control" 6 "Enable maximum electric power control" 253 "Requested mode not supported " 254 "Error or reserved" 255 "Not available/Don't care " ;
VAL_ 2566704384 DriveStrategyPriority3 0 "Enable maximum draft power control " 1 "Enable constant PTO speed control" 2 "Enable wheel speed/PTO speed ratio control" 3 "Enable minimum engine speed control" 4 "Enable engine economy control " 5 "Enable maximum hydraulic power control" 6 "Enable maximum electric power control" 253 "Requested mode not supported " 254 "Error or reserved" 255 "Not available/Don't care " ;
VAL_ 2566704384 DriveStrategyPriority4 0 "Enable maximum draft power control " 1 "Enable constant PTO speed control" 2 "Enable wheel speed/PTO speed ratio control" 3 "Enable minimum engine speed control" 4 "Enable engine economy control " 5 "Enable maximum hydraulic power control" 6 "Enable maximum electric power control" 253 "Requested mode not supported " 254 "Error or reserved" 255 "Not available/Don't care " ;
VAL_ 2566704384 DriveStrategyRequestState 0 "External Request Accepted. No subsequent operator intervention" 1 "Control override (most recent external request ignored)" 2 "Error indication " 3 "Not available/Not Installed " ;
VAL_ 2365378048 DriveStrategyPriority1Req 0 "Enable maximum draft power control " 1 "Enable constant PTO speed control" 2 "Enable wheel speed/PTO speed ratio control" 3 "Enable minimum engine speed control" 4 "Enable engine economy control " 5 "Enable maximum hydraulic power control" 6 "Enable maximum electric power control" 254 "Error or reserved" 255 "Not available/Don't care " ;
VAL_ 2365378048 DriveStrategyPriority2Req 0 "Enable maximum draft power control " 1 "Enable constant PTO speed control" 2 "Enable wheel speed/PTO speed ratio control" 3 "Enable minimum engine speed control" 4 "Enable engine economy control " 5 "Enable maximum hydraulic power control" 6 "Enable maximum electric power control" 254 "Error or reserved" 255 "Not available/Don't care " ;
VAL_ 2365378048 DriveStrategyPriority3Req 0 "Enable maximum draft power control " 1 "Enable constant PTO speed control" 2 "Enable wheel speed/PTO speed ratio control" 3 "Enable minimum engine speed control" 4 "Enable engine economy control " 5 "Enable maximum hydraulic power control" 6 "Enable maximum electric power control" 254 "Error or reserved" 255 "Not available/Don't care " ;
VAL_ 2365378048 DriveStrategyPriority4Req 0 "Enable maximum draft power control " 1 "Enable constant PTO speed control" 2 "Enable wheel speed/PTO speed ratio control" 3 "Enable minimum engine speed control" 4 "Enable engine economy control " 5 "Enable maximum hydraulic power control" 6 "Enable maximum electric power control" 254 "Error or reserved" 255 "Not available/Don't care " ;
VAL_ 2365378048 RestoreOpDriveStratSetReq 0 "No Request (sent when implement does not want setting restored) " 1 "Restore Operator Drive Strategy Setting " 2 "Error indication " 3 "Not available " ;
VAL_ 2566688510 Functionality 0 "Minimum control function  " 1 "Universal terminal (server)" 2 "Universal terminal working set (client) " 3 "Aux-O inputs " 4 "Aux-O functions " 5 "Aux-N inputs " 6 "Aux-N functions " 7 "Task controller basic (server) " 8 "Task controller basic working set (client)" 9 "Task controller geo (server) " 10 "Task controller geo working set (client) " 11 "Task controller section control (server) " 12 "Task controller section control working set (client)" 13 "Basic Tractor ECU (server) " 14 "Basic Tractor ECU implement set (client) " ;
SG_MUL_VAL_ 2358181630 MaxDesignatorStringLength MessageCode 144-144;
SG_MUL_VAL_ 2358181630 BusyFlagParsing MessageCode 149-149;
SG_MUL_VAL_ 2358181630 ReceivedTAN MessageCode 50-50;
SG_MUL_VAL_ 2358181630 RecordedFunctionValue MessageCode 51-51;
SG_MUL_VAL_ 2358181630 BusyFlagMemoryAccess MessageCode 149-149;
SG_MUL_VAL_ 2358181630 ExecutionIndicationResponseError MessageCode 50-50;
SG_MUL_VAL_ 2358181630 TAN MessageCode 51-51, 52-52;
SG_MUL_VAL_ 2358181630 SequenceState MessageCode 149-149;
SG_MUL_VAL_ 2358181630 ReasonIndicator MessageCode 48-48;
SG_MUL_VAL_ 2358181630 GraphicsHeight MessageCode 144-144;
SG_MUL_VAL_ 2358181630 FunctionExecutionState MessageCode 50-50;
SG_MUL_VAL_ 2358181630 FunctionExecutionStateAck MessageCode 52-52;
SG_MUL_VAL_ 2358181630 StateID MessageCode 50-50, 52-52;
SG_MUL_VAL_ 2358181630 ActualConfigurationLabel ConfigLabelResponseError 0-0;
SG_MUL_VAL_ 2358181630 ActualVersionLabel VersionResponseError 0-0;
SG_MUL_VAL_ 2358181630 GraphicsWidth MessageCode 144-144;
SG_MUL_VAL_ 2358181630 RecordedStateID MessageCode 51-51;
SG_MUL_VAL_ 2358181630 SequenceNumber MessageCode 149-149;
SG_MUL_VAL_ 2358181630 ObjectIdOfFirstFaultyObject MessageCode 4-4;
SG_MUL_VAL_ 2358181630 RecordedFunctionID MessageCode 51-51, 52-52;
SG_MUL_VAL_ 2358181630 MemoryStatus MessageCode 145-145;
SG_MUL_VAL_ 2358181630 VersionResponseError MessageCode 1-1;
SG_MUL_VAL_ 2358181630 ConfigLabelResponseError MessageCode 2-2;
SG_MUL_VAL_ 2358181630 TransferResponseError MessageCode 3-3;
SG_MUL_VAL_ 2358181630 ActivationResponseError MessageCode 4-4;
SG_MUL_VAL_ 2358181630 SCMState MessageCode 149-149;
SG_MUL_VAL_ 2358181630 FunctionID MessageCode 50-50;
SG_MUL_VAL_ 2358181630 SCVersion MessageCode 144-144;
SG_MUL_VAL_ 2358181630 CommandedSCCState MessageCode 48-48;
SG_MUL_VAL_ 2358181630 DeleteCommandResponseError MessageCode 5-5;
SG_MUL_VAL_ 2358181630 StoreCommandError MessageCode 6-6;
SG_MUL_VAL_ 2358181630 LoadResponseError MessageCode 7-7;
SG_MUL_VAL_ 2358116094 OperatorConfirmationRequired3 NumberOfFaultyFunctions 3-255;
SG_MUL_VAL_ 2358116094 ClientFunctionErrorStatuts3 NumberOfFaultyFunctions 3-255;
SG_MUL_VAL_ 2358116094 IDOfFaultyClientFunction3 NumberOfFaultyFunctions 3-255;
SG_MUL_VAL_ 2358116094 OperatorConfirmationRequired2 NumberOfFaultyFunctions 2-255;
SG_MUL_VAL_ 2358116094 ClientFunctionErrorStatuts2 NumberOfFaultyFunctions 2-255;
SG_MUL_VAL_ 2358116094 ReceivedTAN MessageCode 52-52;
SG_MUL_VAL_ 2358116094 FunctionValue FunctionExecutionState 0-0, 2-2;
SG_MUL_VAL_ 2358116094 IDOfFaultyClientFunction2 NumberOfFaultyFunctions 2-255;
SG_MUL_VAL_ 2358116094 ClientFunctonErrorState MessageCode 150-150;
SG_MUL_VAL_ 2358116094 OperatorConfirmationRequired1 NumberOfFaultyFunctions 1-255;
SG_MUL_VAL_ 2358116094 TAN MessageCode 50-50;
SG_MUL_VAL_ 2358116094 ClientExecutionError MessageCode 52-52;
SG_MUL_VAL_ 2358116094 ClientFunctionErrorStatuts1 NumberOfFaultyFunctions 1-255;
SG_MUL_VAL_ 2358116094 ClientAbortError MessageCode 49-49;
SG_MUL_VAL_ 2358116094 SequenceState MessageCode 150-150;
SG_MUL_VAL_ 2358116094 FunctionExecutionState MessageCode 50-50;
SG_MUL_VAL_ 2358116094 NewFunctionExecutionState MessageCode 52-52;
SG_MUL_VAL_ 2358116094 NewStateID MessageCode 52-52;
SG_MUL_VAL_ 2358116094 IDOfFaultyClientFunction1 NumberOfFaultyFunctions 1-255;
SG_MUL_VAL_ 2358116094 StateID MessageCode 50-50;
SG_MUL_VAL_ 2358116094 SequenceNumber MessageCode 150-150;
SG_MUL_VAL_ 2358116094 NumberOfFaultyFunctions MessageCode 53-53;
SG_MUL_VAL_ 2358116094 RecordedFunctionID MessageCode 52-52;
SG_MUL_VAL_ 2358116094 SCCState MessageCode 150-150;
SG_MUL_VAL_ 2358116094 FunctionID MessageCode 50-50;
SG_MUL_VAL_ 2358116094 MemoryRequired MessageCode 145-145;
SG_MUL_VAL_ 2358116094 AddressSCCWSM MessageCode 4-4;
SG_MUL_VAL_ 2358116094 DeleteCommandType MessageCode 5-5;
SG_MUL_VAL_ 2559835902 ManufacturerCodeQualifierFlag NMControlModeIndicator 0-0, 4-4, 8-8;
SG_MUL_VAL_ 2559835902 ECUInstanceQualifierFlag NMControlModeIndicator 0-0, 4-4, 8-8;
SG_MUL_VAL_ 2559835902 FunctionInstanceQualifierFlag NMControlModeIndicator 0-0, 4-4, 8-8;
SG_MUL_VAL_ 2559835902 FunctionQualifierFlag NMControlModeIndicator 0-0, 4-4, 8-8;
SG_MUL_VAL_ 2559835902 VehicleSystemQualifierFlag NMControlModeIndicator 0-0, 4-4, 8-8;
SG_MUL_VAL_ 2559835902 VehicleSystemInstanceQualifierFl NMControlModeIndicator 0-0, 4-4, 8-8;
SG_MUL_VAL_ 2559835902 IndustryGroupQualifierFlag NMControlModeIndicator 0-0, 4-4, 8-8;
SG_MUL_VAL_ 2559835902 ArbitraryAddressCapableQualifier NMControlModeIndicator 0-0, 4-4, 8-8;
SG_MUL_VAL_ 2559835902 CommandManufacturerCode NMControlModeIndicator 0-3, 8-8;
SG_MUL_VAL_ 2559835902 CommandECUInstance NMControlModeIndicator 0-3, 8-8;
SG_MUL_VAL_ 2559835902 CommandFunctionInstance NMControlModeIndicator 0-3, 8-8;
SG_MUL_VAL_ 2559835902 CommandFunction NMControlModeIndicator 0-3, 8-8;
SG_MUL_VAL_ 2559835902 CommandVehicleSystem NMControlModeIndicator 0-3, 8-8;
SG_MUL_VAL_ 2559835902 CommandIndustryGroup NMControlModeIndicator 0-3, 8-8;
SG_MUL_VAL_ 2559835902 CommandVehicleSystemInstance NMControlModeIndicator 0-3, 8-8;
SG_MUL_VAL_ 2559835902 CommandArbitraryAddressCapable NMControlModeIndicator 0-3, 8-8;
